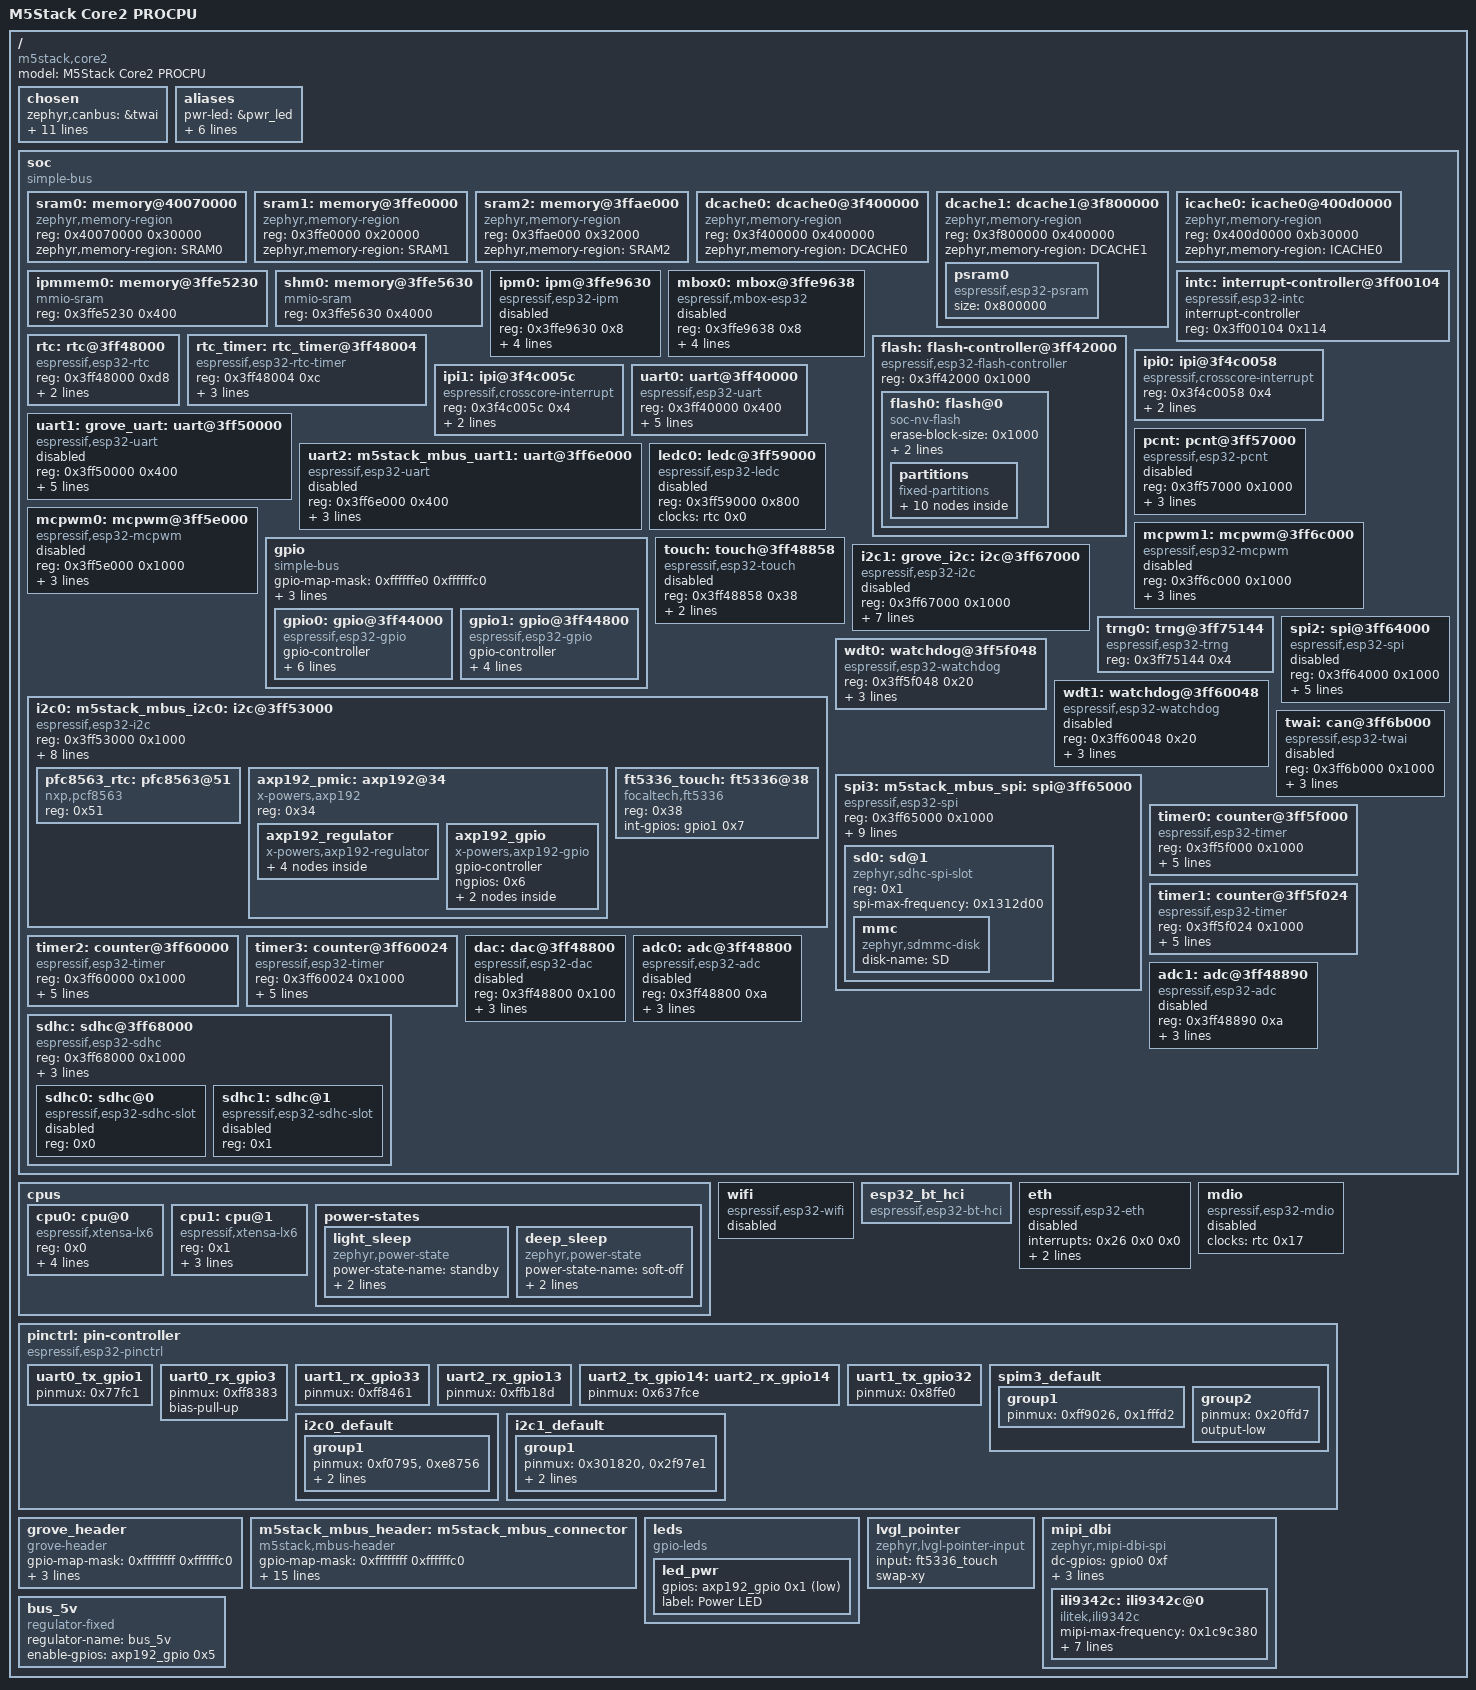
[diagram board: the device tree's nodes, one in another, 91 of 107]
/dts-v1/;

/ {
	#address-cells = < 0x1 >;
	#size-cells = < 0x1 >;
	model = "M5Stack Core2 PROCPU";
	compatible = "m5stack,core2";
	chosen {
		zephyr,canbus = &twai;
		zephyr,entropy = &trng0;
		zephyr,flash-controller = &flash;
		zephyr,bt-hci = &esp32_bt_hci;
		zephyr,sram = &sram1;
		zephyr,console = &uart0;
		zephyr,shell-uart = &uart0;
		zephyr,flash = &flash0;
		zephyr,display = &ili9342c;
		zephyr,code-partition = &slot0_partition;
		zephyr,rtc = &pfc8563_rtc;
		zephyr,touch = &ft5336_touch;
	};
	aliases {
		pwr-led = &pwr_led;
		uart-0 = &uart0;
		i2c-0 = &i2c0;
		watchdog0 = &wdt0;
		rtc = &pfc8563_rtc;
		led0 = &led_pwr;
		sdhc0 = &sd0;
	};
	soc {
		#address-cells = < 0x1 >;
		#size-cells = < 0x1 >;
		compatible = "simple-bus";
		ranges;
		sram0: memory@40070000 {
			compatible = "zephyr,memory-region", "mmio-sram";
			reg = < 0x40070000 0x30000 >;
			zephyr,memory-region = "SRAM0";
		};
		sram1: memory@3ffe0000 {
			compatible = "zephyr,memory-region", "mmio-sram";
			reg = < 0x3ffe0000 0x20000 >;
			zephyr,memory-region = "SRAM1";
		};
		sram2: memory@3ffae000 {
			compatible = "zephyr,memory-region", "mmio-sram";
			reg = < 0x3ffae000 0x32000 >;
			zephyr,memory-region = "SRAM2";
		};
		dcache0: dcache0@3f400000 {
			compatible = "zephyr,memory-region", "mmio-sram";
			reg = < 0x3f400000 0x400000 >;
			zephyr,memory-region = "DCACHE0";
		};
		dcache1: dcache1@3f800000 {
			compatible = "zephyr,memory-region", "mmio-sram";
			reg = < 0x3f800000 0x400000 >;
			zephyr,memory-region = "DCACHE1";
			psram0: psram0 {
				compatible = "espressif,esp32-psram";
				size = < 0x800000 >;
			};
		};
		icache0: icache0@400d0000 {
			compatible = "zephyr,memory-region", "mmio-sram";
			reg = < 0x400d0000 0xb30000 >;
			zephyr,memory-region = "ICACHE0";
		};
		ipmmem0: memory@3ffe5230 {
			compatible = "mmio-sram";
			reg = < 0x3ffe5230 0x400 >;
			phandle = < 0x1 >;
		};
		shm0: memory@3ffe5630 {
			compatible = "mmio-sram";
			reg = < 0x3ffe5630 0x4000 >;
		};
		ipm0: ipm@3ffe9630 {
			compatible = "espressif,esp32-ipm";
			reg = < 0x3ffe9630 0x8 >;
			status = "disabled";
			shared-memory = < &ipmmem0 >;
			shared-memory-size = < 0x400 >;
			interrupts = < 0x18 0x0 0x0 >, < 0x19 0x0 0x0 >;
			interrupt-parent = < &intc >;
		};
		mbox0: mbox@3ffe9638 {
			compatible = "espressif,mbox-esp32";
			reg = < 0x3ffe9638 0x8 >;
			status = "disabled";
			shared-memory = < &ipmmem0 >;
			shared-memory-size = < 0x400 >;
			interrupts = < 0x18 0x0 0x0 >, < 0x19 0x0 0x0 >;
			interrupt-parent = < &intc >;
			#mbox-cells = < 0x1 >;
		};
		intc: interrupt-controller@3ff00104 {
			#interrupt-cells = < 0x3 >;
			#address-cells = < 0x0 >;
			compatible = "espressif,esp32-intc";
			interrupt-controller;
			reg = < 0x3ff00104 0x114 >;
			status = "okay";
			phandle = < 0x2 >;
		};
		rtc: rtc@3ff48000 {
			compatible = "espressif,esp32-rtc";
			reg = < 0x3ff48000 0xd8 >;
			fast-clk-src = < 0x1 >;
			slow-clk-src = < 0x0 >;
			#clock-cells = < 0x1 >;
			status = "okay";
			phandle = < 0x3 >;
		};
		rtc_timer: rtc_timer@3ff48004 {
			reg = < 0x3ff48004 0xc >;
			compatible = "espressif,esp32-rtc-timer";
			clocks = < &rtc 0x22 >;
			interrupts = < 0x2e 0x0 0x0 >;
			interrupt-parent = < &intc >;
			status = "okay";
		};
		flash: flash-controller@3ff42000 {
			compatible = "espressif,esp32-flash-controller";
			reg = < 0x3ff42000 0x1000 >;
			#address-cells = < 0x1 >;
			#size-cells = < 0x1 >;
			flash0: flash@0 {
				compatible = "soc-nv-flash";
				erase-block-size = < 0x1000 >;
				write-block-size = < 0x4 >;
				reg = < 0x0 0x1000000 >;
				partitions {
					compatible = "fixed-partitions";
					#address-cells = < 0x1 >;
					#size-cells = < 0x1 >;
					boot_partition: partition@1000 {
						label = "mcuboot";
						reg = < 0x1000 0x1f000 >;
					};
					slot0_partition: partition@20000 {
						label = "image-0";
						reg = < 0x20000 0x150000 >;
					};
					slot1_partition: partition@170000 {
						label = "image-1";
						reg = < 0x170000 0x150000 >;
					};
					slot0_appcpu_partition: partition@2c0000 {
						label = "image-0-appcpu";
						reg = < 0x2c0000 0x70000 >;
					};
					slot1_appcpu_partition: partition@330000 {
						label = "image-1-appcpu";
						reg = < 0x330000 0x70000 >;
					};
					slot0_lpcore_partition: partition@3a0000 {
						label = "image-0-lpcore";
						reg = < 0x3a0000 0x8000 >;
					};
					slot1_lpcore_partition: partition@3a8000 {
						label = "image-1-lpcore";
						reg = < 0x3a8000 0x8000 >;
					};
					storage_partition: partition@3b0000 {
						label = "storage";
						reg = < 0x3b0000 0x30000 >;
					};
					scratch_partition: partition@3e0000 {
						label = "image-scratch";
						reg = < 0x3e0000 0x1f000 >;
					};
					coredump_partition: partition@3ff000 {
						label = "coredump";
						reg = < 0x3ff000 0x1000 >;
					};
				};
			};
		};
		ipi0: ipi@3f4c0058 {
			compatible = "espressif,crosscore-interrupt";
			reg = < 0x3f4c0058 0x4 >;
			interrupts = < 0x18 0x0 0x0 >;
			interrupt-parent = < &intc >;
		};
		ipi1: ipi@3f4c005c {
			compatible = "espressif,crosscore-interrupt";
			reg = < 0x3f4c005c 0x4 >;
			interrupts = < 0x19 0x0 0x0 >;
			interrupt-parent = < &intc >;
		};
		uart0: uart@3ff40000 {
			compatible = "espressif,esp32-uart";
			reg = < 0x3ff40000 0x400 >;
			interrupts = < 0x22 0x0 0x0 >;
			interrupt-parent = < &intc >;
			clocks = < &rtc 0x1 >;
			status = "okay";
			current-speed = < 0x1c200 >;
			pinctrl-0 = < &uart0_tx_gpio1 &uart0_rx_gpio3 >;
			pinctrl-names = "default";
		};
		uart1: grove_uart: m5stack_mbus_uart0: uart@3ff50000 {
			compatible = "espressif,esp32-uart";
			reg = < 0x3ff50000 0x400 >;
			interrupts = < 0x23 0x0 0x0 >;
			interrupt-parent = < &intc >;
			clocks = < &rtc 0x2 >;
			status = "disabled";
			current-speed = < 0x1c200 >;
			pinctrl-0 = < &uart1_rx_gpio33 &uart1_tx_gpio32 >;
			pinctrl-names = "default";
		};
		uart2: m5stack_mbus_uart1: uart@3ff6e000 {
			compatible = "espressif,esp32-uart";
			reg = < 0x3ff6e000 0x400 >;
			interrupts = < 0x24 0x0 0x0 >;
			interrupt-parent = < &intc >;
			clocks = < &rtc 0x3 >;
			status = "disabled";
		};
		pcnt: pcnt@3ff57000 {
			compatible = "espressif,esp32-pcnt";
			reg = < 0x3ff57000 0x1000 >;
			interrupts = < 0x30 0x0 0x0 >;
			interrupt-parent = < &intc >;
			clocks = < &rtc 0xf >;
			status = "disabled";
		};
		ledc0: ledc@3ff59000 {
			compatible = "espressif,esp32-ledc";
			#pwm-cells = < 0x3 >;
			reg = < 0x3ff59000 0x800 >;
			clocks = < &rtc 0x0 >;
			status = "disabled";
		};
		mcpwm0: mcpwm@3ff5e000 {
			compatible = "espressif,esp32-mcpwm";
			reg = < 0x3ff5e000 0x1000 >;
			interrupts = < 0x27 0x0 0x0 >;
			interrupt-parent = < &intc >;
			clocks = < &rtc 0xa >;
			#pwm-cells = < 0x3 >;
			status = "disabled";
		};
		mcpwm1: mcpwm@3ff6c000 {
			compatible = "espressif,esp32-mcpwm";
			reg = < 0x3ff6c000 0x1000 >;
			interrupts = < 0x28 0x0 0x0 >;
			interrupt-parent = < &intc >;
			clocks = < &rtc 0xb >;
			#pwm-cells = < 0x3 >;
			status = "disabled";
		};
		gpio: gpio {
			compatible = "simple-bus";
			gpio-map-mask = < 0xffffffe0 0xffffffc0 >;
			gpio-map-pass-thru = < 0x1f 0x3f >;
			gpio-map = < 0x0 0x0 &gpio0 0x0 0x0 0x20 0x0 &gpio1 0x0 0x0 >;
			#gpio-cells = < 0x2 >;
			#address-cells = < 0x1 >;
			#size-cells = < 0x1 >;
			ranges;
			gpio0: gpio@3ff44000 {
				compatible = "espressif,esp32-gpio";
				gpio-controller;
				#gpio-cells = < 0x2 >;
				reg = < 0x3ff44000 0x800 >;
				interrupts = < 0x16 0x0 0x0 >;
				interrupt-parent = < &intc >;
				ngpios = < 0x20 >;
				gpio-reserved-ranges = < 0x14 0x1 >, < 0x18 0x1 >, < 0x1c 0x4 >;
				status = "okay";
				phandle = < 0x8 >;
			};
			gpio1: gpio@3ff44800 {
				compatible = "espressif,esp32-gpio";
				gpio-controller;
				#gpio-cells = < 0x2 >;
				reg = < 0x3ff44800 0x800 >;
				interrupts = < 0x16 0x0 0x0 >;
				interrupt-parent = < &intc >;
				ngpios = < 0x8 >;
				status = "okay";
				phandle = < 0x9 >;
			};
		};
		touch: touch@3ff48858 {
			compatible = "espressif,esp32-touch";
			reg = < 0x3ff48858 0x38 >;
			interrupts = < 0x2e 0x0 0x0 >;
			interrupt-parent = < &intc >;
			status = "disabled";
		};
		i2c0: m5stack_mbus_i2c0: i2c@3ff53000 {
			compatible = "espressif,esp32-i2c";
			#address-cells = < 0x1 >;
			#size-cells = < 0x0 >;
			reg = < 0x3ff53000 0x1000 >;
			interrupts = < 0x31 0x0 0x0 >;
			interrupt-parent = < &intc >;
			clocks = < &rtc 0x4 >;
			status = "okay";
			clock-frequency = < 0x61a80 >;
			sda-gpios = < &gpio0 0x15 0x6 >;
			scl-gpios = < &gpio0 0x16 0x6 >;
			pinctrl-0 = < &i2c0_default >;
			scl-timeout-us = < 0x0 >;
			pinctrl-names = "default";
			pfc8563_rtc: pfc8563@51 {
				compatible = "nxp,pcf8563";
				reg = < 0x51 >;
				status = "okay";
			};
			axp192_pmic: axp192@34 {
				compatible = "x-powers,axp192";
				reg = < 0x34 >;
				status = "okay";
				axp192_regulator: axp192_regulator {
					compatible = "x-powers,axp192-regulator";
					status = "okay";
					vdd_mcu: DCDC1 {
						regulator-init-microvolt = < 0x331df0 >;
						regulator-min-microvolt = < 0x30d400 >;
						regulator-max-microvolt = < 0x33e140 >;
						regulator-initial-mode = < 0x0 >;
						regulator-boot-on;
						regulator-always-on;
					};
					lcd_bg: DCDC3 {
						regulator-init-microvolt = < 0x2ab980 >;
						regulator-min-microvolt = < 0x2625a0 >;
						regulator-max-microvolt = < 0x325aa0 >;
						regulator-boot-on;
						phandle = < 0x12 >;
					};
					v_peri: LDO2 {
						regulator-init-microvolt = < 0x325aa0 >;
						regulator-min-microvolt = < 0x30d400 >;
						regulator-max-microvolt = < 0x325aa0 >;
						regulator-boot-on;
					};
					vib_motor: LDO3 {
						regulator-init-microvolt = < 0x2ab980 >;
					};
				};
				axp192_gpio: axp192_gpio {
					compatible = "x-powers,axp192-gpio";
					gpio-controller;
					#gpio-cells = < 0x2 >;
					ngpios = < 0x6 >;
					status = "okay";
					phandle = < 0xf >;
					pwr_led: axp192_gpio1 {
						gpio-hog;
						gpios = < 0x1 0x7 >;
						output-high;
						line-name = "pwr-led";
					};
					bus_pwr_en: axp192_gpio0 {
						gpio-hog;
						gpios = < 0x0 0x0 >;
						output-high;
						line-name = "bus_pwr_en";
					};
				};
			};
			ft5336_touch: ft5336@38 {
				compatible = "focaltech,ft5336";
				reg = < 0x38 >;
				int-gpios = < &gpio1 0x7 0x0 >;
				phandle = < 0x10 >;
			};
		};
		i2c1: grove_i2c: m5stack_mbus_i2c1: i2c@3ff67000 {
			compatible = "espressif,esp32-i2c";
			#address-cells = < 0x1 >;
			#size-cells = < 0x0 >;
			reg = < 0x3ff67000 0x1000 >;
			interrupts = < 0x32 0x0 0x0 >;
			interrupt-parent = < &intc >;
			clocks = < &rtc 0x5 >;
			status = "disabled";
			clock-frequency = < 0x186a0 >;
			sda-gpios = < &gpio1 0x0 0x6 >;
			scl-gpios = < &gpio1 0x1 0x6 >;
			pinctrl-0 = < &i2c1_default >;
			pinctrl-names = "default";
		};
		trng0: trng@3ff75144 {
			compatible = "espressif,esp32-trng";
			reg = < 0x3ff75144 0x4 >;
			status = "okay";
		};
		wdt0: watchdog@3ff5f048 {
			compatible = "espressif,esp32-watchdog";
			reg = < 0x3ff5f048 0x20 >;
			interrupts = < 0x10 0x0 0x0 >;
			interrupt-parent = < &intc >;
			clocks = < &rtc 0x8 >;
			status = "okay";
		};
		wdt1: watchdog@3ff60048 {
			compatible = "espressif,esp32-watchdog";
			reg = < 0x3ff60048 0x20 >;
			interrupts = < 0x14 0x0 0x0 >;
			interrupt-parent = < &intc >;
			clocks = < &rtc 0x9 >;
			status = "disabled";
		};
		spi2: spi@3ff64000 {
			compatible = "espressif,esp32-spi";
			reg = < 0x3ff64000 0x1000 >;
			interrupts = < 0x1e 0x0 0x0 >;
			interrupt-parent = < &intc >;
			clocks = < &rtc 0x11 >;
			dma-clk = < 0x13 >;
			dma-host = < 0x0 >;
			status = "disabled";
		};
		spi3: m5stack_mbus_spi: spi@3ff65000 {
			compatible = "espressif,esp32-spi";
			reg = < 0x3ff65000 0x1000 >;
			interrupts = < 0x1f 0x0 0x0 >;
			interrupt-parent = < &intc >;
			clocks = < &rtc 0x12 >;
			dma-clk = < 0x13 >;
			dma-host = < 0x1 >;
			status = "okay";
			#address-cells = < 0x1 >;
			#size-cells = < 0x0 >;
			pinctrl-0 = < &spim3_default >;
			pinctrl-names = "default";
			dma-enabled;
			clock-frequency = < 0x1312d00 >;
			cs-gpios = < &gpio0 0x5 0x1 >, < &gpio0 0x4 0x1 >;
			phandle = < 0x11 >;
			sd0: sd@1 {
				compatible = "zephyr,sdhc-spi-slot";
				reg = < 0x1 >;
				status = "okay";
				spi-max-frequency = < 0x1312d00 >;
				mmc {
					compatible = "zephyr,sdmmc-disk";
					disk-name = "SD";
					status = "okay";
				};
			};
		};
		twai: can@3ff6b000 {
			compatible = "espressif,esp32-twai";
			reg = < 0x3ff6b000 0x1000 >;
			interrupts = < 0x2d 0x0 0x0 >;
			interrupt-parent = < &intc >;
			clocks = < &rtc 0x16 >;
			status = "disabled";
		};
		timer0: counter@3ff5f000 {
			compatible = "espressif,esp32-timer";
			reg = < 0x3ff5f000 0x1000 >;
			clocks = < &rtc 0x8 >;
			group = < 0x0 >;
			index = < 0x0 >;
			interrupts = < 0xe 0x0 0x0 >;
			interrupt-parent = < &intc >;
			status = "okay";
		};
		timer1: counter@3ff5f024 {
			compatible = "espressif,esp32-timer";
			reg = < 0x3ff5f024 0x1000 >;
			clocks = < &rtc 0x8 >;
			group = < 0x0 >;
			index = < 0x1 >;
			interrupts = < 0xf 0x0 0x0 >;
			interrupt-parent = < &intc >;
			status = "okay";
		};
		timer2: counter@3ff60000 {
			compatible = "espressif,esp32-timer";
			reg = < 0x3ff60000 0x1000 >;
			clocks = < &rtc 0x9 >;
			group = < 0x1 >;
			index = < 0x0 >;
			interrupts = < 0x12 0x0 0x0 >;
			interrupt-parent = < &intc >;
			status = "okay";
		};
		timer3: counter@3ff60024 {
			compatible = "espressif,esp32-timer";
			reg = < 0x3ff60024 0x1000 >;
			clocks = < &rtc 0x9 >;
			group = < 0x1 >;
			index = < 0x1 >;
			interrupts = < 0x13 0x0 0x0 >;
			interrupt-parent = < &intc >;
			status = "okay";
		};
		dac: dac@3ff48800 {
			compatible = "espressif,esp32-dac";
			reg = < 0x3ff48800 0x100 >;
			interrupts = < 0x2e 0x0 0x0 >;
			interrupt-parent = < &intc >;
			clocks = < &rtc 0x21 >;
			#io-channel-cells = < 0x1 >;
			status = "disabled";
		};
		adc0: adc@3ff48800 {
			compatible = "espressif,esp32-adc";
			reg = < 0x3ff48800 0xa >;
			clocks = < &rtc 0x21 >;
			unit = < 0x1 >;
			channel-count = < 0x8 >;
			#io-channel-cells = < 0x1 >;
			status = "disabled";
		};
		adc1: adc@3ff48890 {
			compatible = "espressif,esp32-adc";
			reg = < 0x3ff48890 0xa >;
			clocks = < &rtc 0x21 >;
			unit = < 0x2 >;
			channel-count = < 0xa >;
			#io-channel-cells = < 0x1 >;
			status = "disabled";
		};
		sdhc: sdhc@3ff68000 {
			compatible = "espressif,esp32-sdhc";
			reg = < 0x3ff68000 0x1000 >;
			interrupts = < 0x25 0x0 0x0 >;
			interrupt-parent = < &intc >;
			clocks = < &rtc 0x14 >;
			#address-cells = < 0x1 >;
			#size-cells = < 0x0 >;
			sdhc0: sdhc@0 {
				compatible = "espressif,esp32-sdhc-slot";
				reg = < 0x0 >;
				status = "disabled";
			};
			sdhc1: sdhc@1 {
				compatible = "espressif,esp32-sdhc-slot";
				reg = < 0x1 >;
				status = "disabled";
			};
		};
	};
	cpus {
		#address-cells = < 0x1 >;
		#size-cells = < 0x0 >;
		cpu0: cpu@0 {
			device_type = "cpu";
			compatible = "espressif,xtensa-lx6";
			reg = < 0x0 >;
			cpu-power-states = < &light_sleep &deep_sleep >;
			clock-source = < 0x1 >;
			clock-frequency = < 0xe4e1c00 >;
			xtal-freq = < 0x2625a00 >;
		};
		cpu1: cpu@1 {
			device_type = "cpu";
			compatible = "espressif,xtensa-lx6";
			reg = < 0x1 >;
			clock-source = < 0x1 >;
			clock-frequency = < 0xe4e1c00 >;
			xtal-freq = < 0x2625a00 >;
		};
		power-states {
			light_sleep: light_sleep {
				compatible = "zephyr,power-state";
				power-state-name = "standby";
				min-residency-us = < 0xc8 >;
				exit-latency-us = < 0x3c >;
				phandle = < 0xd >;
			};
			deep_sleep: deep_sleep {
				compatible = "zephyr,power-state";
				power-state-name = "soft-off";
				min-residency-us = < 0x7d0 >;
				exit-latency-us = < 0xd4 >;
				phandle = < 0xe >;
			};
		};
	};
	wifi: wifi {
		compatible = "espressif,esp32-wifi";
		status = "disabled";
	};
	esp32_bt_hci: esp32_bt_hci {
		compatible = "espressif,esp32-bt-hci";
		status = "okay";
	};
	eth: eth {
		compatible = "espressif,esp32-eth";
		interrupts = < 0x26 0x0 0x0 >;
		interrupt-parent = < &intc >;
		clocks = < &rtc 0x17 >;
		status = "disabled";
	};
	mdio: mdio {
		compatible = "espressif,esp32-mdio";
		clocks = < &rtc 0x17 >;
		status = "disabled";
		#address-cells = < 0x1 >;
		#size-cells = < 0x0 >;
	};
	pinctrl: pin-controller {
		compatible = "espressif,esp32-pinctrl";
		status = "okay";
		uart0_tx_gpio1: uart0_tx_gpio1 {
			pinmux = < 0x77fc1 >;
			phandle = < 0x4 >;
		};
		uart0_rx_gpio3: uart0_rx_gpio3 {
			pinmux = < 0xff8383 >;
			bias-pull-up;
			phandle = < 0x5 >;
		};
		uart1_rx_gpio33: uart1_rx_gpio33 {
			pinmux = < 0xff8461 >;
			phandle = < 0x6 >;
		};
		uart2_rx_gpio13: uart2_rx_gpio13 {
			pinmux = < 0xffb18d >;
		};
		uart2_tx_gpio14: uart2_rx_gpio14 {
			pinmux = < 0x637fce >;
		};
		uart1_tx_gpio32: uart1_tx_gpio32 {
			pinmux = < 0x8ffe0 >;
			phandle = < 0x7 >;
		};
		spim3_default: spim3_default {
			phandle = < 0xc >;
			group1 {
				pinmux = < 0xff9026 >, < 0x1fffd2 >;
			};
			group2 {
				pinmux = < 0x20ffd7 >;
				output-low;
			};
		};
		i2c0_default: i2c0_default {
			phandle = < 0xa >;
			group1 {
				pinmux = < 0xf0795 >, < 0xe8756 >;
				drive-open-drain;
				output-high;
			};
		};
		i2c1_default: i2c1_default {
			phandle = < 0xb >;
			group1 {
				pinmux = < 0x301820 >, < 0x2f97e1 >;
				drive-open-drain;
				output-high;
			};
		};
	};
	grove_header: grove_header {
		compatible = "grove-header";
		#gpio-cells = < 0x2 >;
		gpio-map-mask = < 0xffffffff 0xffffffc0 >;
		gpio-map-pass-thru = < 0x0 0x3f >;
		gpio-map = < 0x0 0x0 &gpio1 0x1 0x0 >, < 0x1 0x0 &gpio1 0x0 0x0 >;
	};
	m5stack_mbus_header: m5stack_mbus_connector {
		compatible = "m5stack,mbus-header";
		#gpio-cells = < 0x2 >;
		gpio-map-mask = < 0xffffffff 0xffffffc0 >;
		gpio-map-pass-thru = < 0x0 0x3f >;
		gpio-map = < 0x1 0x0 &gpio1 0x4 0x0 >, < 0x3 0x0 &gpio1 0x5 0x0 >, < 0x6 0x0 &gpio0 0x17 0x0 >, < 0x7 0x0 &gpio0 0x19 0x0 >, < 0x8 0x0 &gpio1 0x7 0x0 >, < 0x9 0x0 &gpio0 0x1a 0x0 >, < 0xa 0x0 &gpio0 0x12 0x0 >, < 0xc 0x0 &gpio0 0x3 0x0 >, < 0xd 0x0 &gpio0 0x1 0x0 >, < 0xe 0x0 &gpio0 0xd 0x0 >, < 0xf 0x0 &gpio0 0xe 0x0 >, < 0x10 0x0 &gpio0 0x15 0x0 >, < 0x11 0x0 &gpio0 0x16 0x0 >, < 0x12 0x0 &gpio1 0x0 0x0 >, < 0x13 0x0 &gpio1 0x1 0x0 >, < 0x14 0x0 &gpio0 0x1b 0x0 >, < 0x15 0x0 &gpio0 0x13 0x0 >, < 0x16 0x0 &gpio0 0x2 0x0 >, < 0x17 0x0 &gpio0 0x0 0x0 >, < 0x19 0x0 &gpio1 0x3 0x0 >;
	};
	leds {
		compatible = "gpio-leds";
		led_pwr: led_pwr {
			gpios = < &axp192_gpio 0x1 0x7 >;
			label = "Power LED";
		};
	};
	lvgl_pointer {
		compatible = "zephyr,lvgl-pointer-input";
		input = < &ft5336_touch >;
		swap-xy;
	};
	mipi_dbi {
		compatible = "zephyr,mipi-dbi-spi";
		dc-gpios = < &gpio0 0xf 0x0 >;
		reset-gpios = < &axp192_gpio 0x4 0x7 >;
		spi-dev = < &spi3 >;
		write-only;
		#address-cells = < 0x1 >;
		#size-cells = < 0x0 >;
		ili9342c: ili9342c@0 {
			compatible = "ilitek,ili9342c";
			mipi-max-frequency = < 0x1c9c380 >;
			reg = < 0x0 >;
			vin-supply = < &lcd_bg >;
			pixel-format = < 0x0 >;
			display-inversion;
			width = < 0x140 >;
			height = < 0xf0 >;
			rotation = < 0x0 >;
		};
	};
	bus_5v: bus_5v {
		compatible = "regulator-fixed";
		regulator-name = "bus_5v";
		enable-gpios = < &axp192_gpio 0x5 0x0 >;
	};
};
